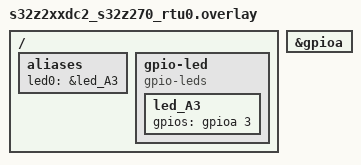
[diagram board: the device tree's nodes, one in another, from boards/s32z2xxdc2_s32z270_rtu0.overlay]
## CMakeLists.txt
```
# SPDX-License-Identifier: Apache-2.0

cmake_minimum_required(VERSION 3.20.0)
find_package(Zephyr REQUIRED HINTS $ENV{ZEPHYR_BASE})
project(gpio_basic_api)

FILE(GLOB app_sources src/*.c)
target_sources(app PRIVATE ${app_sources})
```

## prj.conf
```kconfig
CONFIG_ZTEST=y
CONFIG_GPIO=y
CONFIG_GPIO_GET_DIRECTION=y
```

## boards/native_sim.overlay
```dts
&gpio0 {
	ngpios = <2>;
};
```

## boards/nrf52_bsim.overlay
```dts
/*
 * Copyright (c) 2023 Nordic Semiconductor ASA
 *
 * SPDX-License-Identifier: Apache-2.0
 */

/ {

	aliases {
		led0 = &led0;
	};

	leds {
		compatible = "gpio-leds";
		led0: led_0 {
			gpios = <&gpio0 0 GPIO_ACTIVE_HIGH>;
		};
	};
};
```

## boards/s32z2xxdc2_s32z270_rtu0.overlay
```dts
/*
 * Copyright 2023 NXP
 *
 * SPDX-License-Identifier: Apache-2.0
 */

#include <dt-bindings/gpio/gpio.h>

/ {
	aliases {
		led0 = &led_A3;
	};

	gpio-led {
		compatible = "gpio-leds";
		led_A3: led_A3 {
			gpios = <&gpioa 3 GPIO_ACTIVE_HIGH>;
		};
	};
};

&gpioa {
	status = "okay";
};
```

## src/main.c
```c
/*
 * Copyright (c) 2022 Meta
 *
 * SPDX-License-Identifier: Apache-2.0
 */

#include <zephyr/kernel.h>
#include <zephyr/drivers/gpio.h>
#include <zephyr/ztest.h>

#define TEST_NODE            DT_GPIO_CTLR(DT_ALIAS(led0), gpios)
#define TEST_PIN             DT_GPIO_PIN(DT_ALIAS(led0), gpios)
#define TEST_PIN_DTS_FLAGS   DT_GPIO_FLAGS(DT_ALIAS(led0), gpios)

struct gpio_get_direction_fixture {
	const struct device *port;
	gpio_pin_t pin;
	gpio_flags_t flags;
};

static void *gpio_get_direction_setup(void)
{
	static struct gpio_get_direction_fixture fixture;

	fixture.pin = TEST_PIN;
	fixture.port = DEVICE_DT_GET(TEST_NODE);

	return &fixture;
}

static void gpio_get_direction_before(void *arg)
{
	struct gpio_get_direction_fixture *fixture = (struct gpio_get_direction_fixture *)arg;

	zassert_true(device_is_ready(fixture->port), "GPIO device is not ready");
}

static void common(struct gpio_get_direction_fixture *fixture)
{
	int rv;

	rv = gpio_pin_configure(fixture->port, fixture->pin, fixture->flags);
	if (rv == -ENOTSUP) {
		/* some drivers / hw might not support e.g. input-output or disconnect */
		ztest_test_skip();
	}

	zassert_ok(rv, "gpio_pin_configure() failed: %d", rv);
}

ZTEST_F(gpio_get_direction, test_disconnect)
{
	int rv;

	fixture->flags = GPIO_DISCONNECTED;
	common(fixture);

	rv = gpio_pin_is_input(fixture->port, fixture->pin);
	if (rv == -ENOSYS) {
		/* gpio_pin_direction() is not supported in the driver */
		ztest_test_skip();
	}

	zassert_equal(false, rv, "gpio_pin_is_input() failed: %d", rv);

	rv = gpio_pin_is_output(fixture->port, fixture->pin);
	zassert_equal(false, rv, "gpio_pin_is_output() failed: %d", rv);
}

ZTEST_F(gpio_get_direction, test_input)
{
	int rv;
	fixture->flags = GPIO_INPUT;

	common(fixture);

	rv = gpio_pin_is_input(fixture->port, fixture->pin);
	if (rv == -ENOSYS) {
		/* gpio_pin_direction() is not supported in the driver */
		ztest_test_skip();
	}

	zassert_equal(true, rv, "gpio_pin_is_input() failed: %d", rv);

	rv = gpio_pin_is_output(fixture->port, fixture->pin);
	zassert_equal(false, rv, "gpio_pin_is_output() failed: %d", rv);
}

ZTEST_F(gpio_get_direction, test_output)
{
	int rv;
	fixture->flags = GPIO_OUTPUT | GPIO_OUTPUT_INIT_LOW;

	common(fixture);

	rv = gpio_pin_is_input(fixture->port, fixture->pin);
	if (rv == -ENOSYS) {
		/* gpio_pin_direction() is not supported in the driver */
		ztest_test_skip();
	}

	zassert_equal(false, rv, "gpio_pin_is_input() failed: %d", rv);

	rv = gpio_pin_is_output(fixture->port, fixture->pin);
	zassert_equal(true, rv, "gpio_pin_is_output() failed: %d", rv);
}

ZTEST_F(gpio_get_direction, test_input_output)
{
	int rv;
	fixture->flags = GPIO_INPUT | GPIO_OUTPUT | GPIO_OUTPUT_INIT_LOW;

	common(fixture);

	rv = gpio_pin_is_input(fixture->port, fixture->pin);
	if (rv == -ENOSYS) {
		/* some drivers / gpio hw do not support input-output mode */
		ztest_test_skip();
	}

	zassert_equal(true, rv, "gpio_pin_is_input() failed: %d", rv);

	rv = gpio_pin_is_output(fixture->port, fixture->pin);
	zassert_equal(true, rv, "gpio_pin_is_output() failed: %d", rv);
}

ZTEST_SUITE(gpio_get_direction, NULL, gpio_get_direction_setup, gpio_get_direction_before, NULL,
	    NULL);
```
